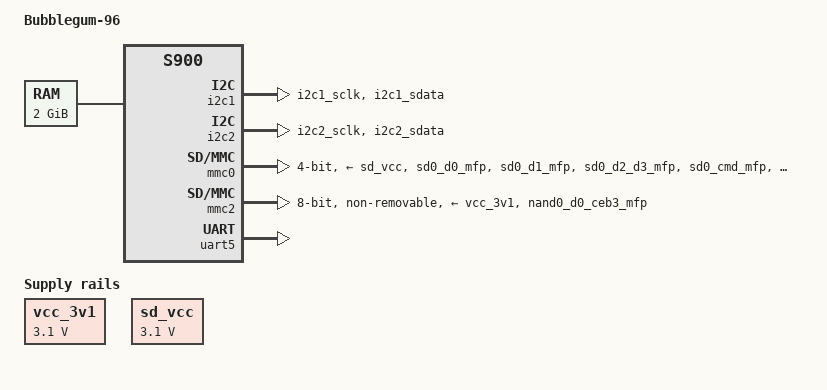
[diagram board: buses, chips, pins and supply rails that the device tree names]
/dts-v1/;
#include "s900.dtsi"
/ {
	compatible = "ucrobotics,bubblegum-96", "actions,s900";
	model = "Bubblegum-96";
	aliases {
		mmc0 = &mmc0;
		mmc1 = &mmc1;
		mmc2 = &mmc2;
		serial5 = &uart5;
	};
	chosen {
		stdout-path = "serial5:115200n8";
	};
	memory@0 {
		device_type = "memory";
		reg = <0x0 0x0 0x0 0x80000000>;
	};
	vcc_3v1: vcc-3v1 {
		compatible = "regulator-fixed";
		regulator-name = "fixed-3.1V";
		regulator-min-microvolt = <3100000>;
		regulator-max-microvolt = <3100000>;
		regulator-always-on;
	};
	sd_vcc: sd-vcc {
		compatible = "regulator-fixed";
		regulator-name = "fixed-3.1V";
		regulator-min-microvolt = <3100000>;
		regulator-max-microvolt = <3100000>;
		regulator-always-on;
	};
};
&i2c0 {
	status = "disabled";
	pinctrl-names = "default";
	pinctrl-0 = <&i2c0_default>;
};
&i2c1 {
	status = "okay";
	pinctrl-names = "default";
	pinctrl-0 = <&i2c1_default>;
};
&i2c2 {
	status = "okay";
	pinctrl-names = "default";
	pinctrl-0 = <&i2c2_default>;
};
&pinctrl {
	gpio-line-names =
		"GPIO-A",  
		"GPIO-B",  
		"GPIO-C",  
		"GPIO-D",  
		"GPIO-E",  
		"GPIO-F",  
		"GPIO-G",  
		"GPIO-H",  
		"GPIO-I",  
		"GPIO-J",  
		"NC",  
		"NC",  
		"SIRQ2_1V8",  
		"PCM0_OUT",  
		"WIFI_LED",  
		"PCM0_SYNC",  
		"PCM0_CLK",  
		"PCM0_IN",  
		"BT_LED",  
		"LED0",  
		"LED1",  
		"JTAG_TCK",  
		"JTAG_TMS",  
		"JTAG_TDI",  
		"JTAG_TDO",  
		"[UART1_RxD]",  
		"NC",  
		"[UART1_TxD]",  
		"SD0_D0",  
		"SD0_D1",  
		"SD0_D2",  
		"SD0_D3",  
		"SD1_D0",  
		"SD1_D1",  
		"SD1_D2",  
		"SD1_D3",  
		"SD0_CMD",  
		"SD0_CLK",  
		"SD1_CMD",  
		"SD1_CLK",  
		"SPI0_SCLK",  
		"SPI0_CS",  
		"SPI0_DIN",  
		"SPI0_DOUT",  
		"I2C5_SDATA",  
		"I2C5_SCLK",  
		"UART0_RX",  
		"UART0_TX",  
		"UART0_RTSB",  
		"UART0_CTSB",  
		"I2C4_SCLK",  
		"I2C4_SDATA",  
		"I2C0_SCLK",  
		"I2C0_SDATA",  
		"I2C1_SCLK",  
		"I2C1_SDATA",  
		"I2C2_SCLK",  
		"I2C2_SDATA",  
		"CSI0_DN0",  
		"CSI0_DP0",  
		"CSI0_DN1",  
		"CSI0_DP1",  
		"CSI0_CN",  
		"CSI0_CP",  
		"CSI0_DN2",  
		"CSI0_DP2",  
		"CSI0_DN3",  
		"CSI0_DP3",  
		"[CLK0]",  
		"CSI1_DN0",  
		"CSI1_DP0",  
		"CSI1_DN1",  
		"CSI1_DP1",  
		"CSI1_CN",  
		"CSI1_CP",  
		"[CLK1]",  
		"[GPIOD0]",  
		"[GPIOD1]",  
		"BT_RST_N",  
		"EXT_DC_EN",  
		"[PCM_DI]",  
		"[PCM_DO]",  
		"[PCM_CLK]",  
		"[PCM_FS]",  
		"WAKE_BT",  
		"WL_REG_ON",  
		"NC",  
		"NC",  
		"NC",  
		"NC",  
		"NC",  
		"WIFI_WAKE",  
		"BT_WAKE",  
		"NC",  
		"OTG_EN2",  
		"OTG_EN",  
		"DSI_DP3",  
		"DSI_DN3",  
		"DSI_DP1",  
		"DSI_DN1",  
		"DSI_CP",  
		"DSI_CN",  
		"DSI_DP0",  
		"DSI_DN0",  
		"DSI_DP2",  
		"DSI_DN2",  
		"N0_D0",  
		"N0_D1",  
		"N0_D2",  
		"N0_D3",  
		"N0_D4",  
		"N0_D5",  
		"N0_D6",  
		"N0_D7",  
		"N0_DQS",  
		"N0_DQSN",  
		"NC",  
		"NC",  
		"NC",  
		"N0_CEB1",  
		"CARD_DT",  
		"N0_CEB3",  
		"SD_DAT0",  
		"SD_DAT1",  
		"SD_DAT2",  
		"SD_DAT3",  
		"NC",  
		"NC",  
		"[PWR_BTN_N]",  
		"[RST_BTN_N]",  
		"NC",  
		"SD_CMD",  
		"GPIO-L",  
		"GPIO-K",  
		"NC",  
		"SD_SCLK",  
		"NC",  
		"JTAG_TRST",  
		"I2C3_SCLK",  
		"LED2",  
		"LED3",  
		"I2C3_SDATA",  
		"UART3_RX",  
		"UART3_TX",  
		"UART3_RTSB",  
		"UART3_CTSB";  
	i2c0_default: i2c0-default {
		pinmux {
			groups = "i2c0_mfp";
			function = "i2c0";
		};
		pinconf {
			pins = "i2c0_sclk", "i2c0_sdata";
			bias-pull-up;
		};
	};
	i2c1_default: i2c1-default {
		pinconf {
			pins = "i2c1_sclk", "i2c1_sdata";
			bias-pull-up;
		};
	};
	i2c2_default: i2c2-default {
		pinconf {
			pins = "i2c2_sclk", "i2c2_sdata";
			bias-pull-up;
		};
	};
	mmc0_default: mmc0_default {
		pinmux {
			groups = "sd0_d0_mfp", "sd0_d1_mfp", "sd0_d2_d3_mfp",
				 "sd0_cmd_mfp", "sd0_clk_mfp";
			function = "sd0";
		};
	};
	mmc2_default: mmc2_default {
		pinmux {
			groups = "nand0_d0_ceb3_mfp";
			function = "sd2";
		};
	};
};
&mmc0 {
	status = "okay";
	pinctrl-names = "default";
	pinctrl-0 = <&mmc0_default>;
	no-sdio;
	no-mmc;
	no-1-8-v;
	cd-gpios = <&pinctrl 120 GPIO_ACTIVE_LOW>;
	bus-width = <4>;
	vmmc-supply = <&sd_vcc>;
	vqmmc-supply = <&sd_vcc>;
};
&mmc2 {
	status = "okay";
	pinctrl-names = "default";
	pinctrl-0 = <&mmc2_default>;
	no-sdio;
	no-sd;
	non-removable;
	bus-width = <8>;
	vmmc-supply = <&vcc_3v1>;
};
&timer {
	clocks = <&hosc>;
};
&uart5 {
	status = "okay";
};
